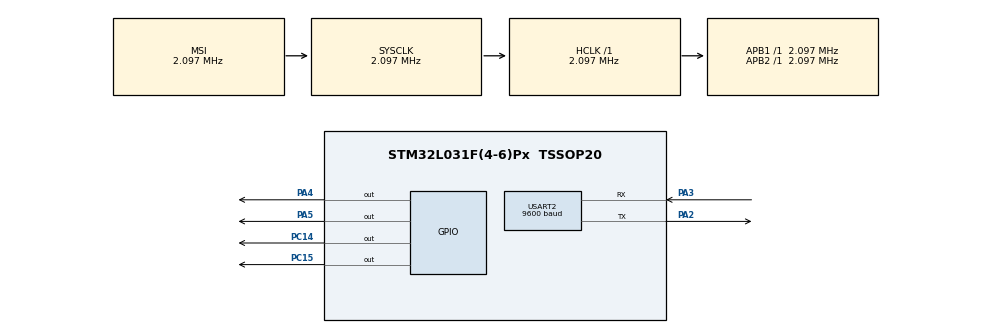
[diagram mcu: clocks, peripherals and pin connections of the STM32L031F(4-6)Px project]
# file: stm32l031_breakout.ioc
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Mcu.Family=STM32L0
Mcu.Name=STM32L031F(4-6)Px
Mcu.Package=TSSOP20
PA13.Mode=Serial_Wire
PA13.Signal=SYS_SWDIO
PA14.Mode=Serial_Wire
PA14.Signal=SYS_SWCLK
PA2.Mode=Asynchronous
PA2.Signal=USART2_TX
PA3.Mode=Asynchronous
PA3.Signal=USART2_RX
PA4.Signal=GPIO_Output
PA5.Signal=GPIO_Output
PC14-OSC32_IN.Signal=GPIO_Output
PC15-OSC32_OUT.Signal=GPIO_Output
ProjectManager.HeapSize=0x200
ProjectManager.StackSize=0x400
ProjectManager.TargetToolchain=SW4STM32
RCC.AHBFreq_Value=2097000
RCC.APB1Freq_Value=2097000
RCC.APB1TimFreq_Value=2097000
RCC.APB2Freq_Value=2097000
RCC.APB2TimFreq_Value=2097000
RCC.HSE_VALUE=8000000
RCC.HSI16_VALUE=16000000
RCC.HSI_VALUE=16000000
RCC.LSE_VALUE=32768
RCC.MSI_VALUE=2097000
RCC.SYSCLKFreq_VALUE=2097000
RCC.VCOOutputFreq_Value=48000000
USART2.BaudRate=9600
USART2.VirtualMode-Asynchronous=VM_ASYNC
board=custom

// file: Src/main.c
/* USER CODE BEGIN Header */
/**
  ******************************************************************************
  * @file           : main.c
  * @brief          : Main program body
  ******************************************************************************
  * @attention
  *
  * <h2><center>&copy; Copyright (c) 2019 STMicroelectronics.
  * All rights reserved.</center></h2>
  *
  * This software component is licensed by ST under BSD 3-Clause license,
  * the "License"; You may not use this file except in compliance with the
  * License. You may obtain a copy of the License at:
  *                        opensource.org/licenses/BSD-3-Clause
  *
  ******************************************************************************
  */
/* USER CODE END Header */

#include "main.h"
#include "usart.h"
#include "gpio.h"

void SystemClock_Config(void);

int main(void)
{

  /* MCU Configuration--------------------------------------------------------*/

  /* Reset of all peripherals, Initializes the Flash interface and the Systick. */
  HAL_Init();

  /* Configure the system clock */
  SystemClock_Config();

  /* Initialize all configured peripherals */
  MX_GPIO_Init();
  MX_USART2_UART_Init();
  /* USER CODE BEGIN 2 */

  HAL_GPIO_WritePin(GPIOA, GPIO_PIN_5, GPIO_PIN_SET);
  HAL_GPIO_WritePin(GPIOA, GPIO_PIN_4, GPIO_PIN_SET);
  HAL_GPIO_WritePin(GPIOC, GPIO_PIN_14|GPIO_PIN_15, GPIO_PIN_SET);
  /* USER CODE END 2 */

  /* Infinite loop */
  while (1)
  {

    /* USER CODE BEGIN 3 */
	HAL_GPIO_TogglePin(GPIOA, GPIO_PIN_5);
	HAL_Delay(500);

  }
  /* USER CODE END 3 */
}

void SystemClock_Config(void)
{
  RCC_OscInitTypeDef RCC_OscInitStruct = {0};
  RCC_ClkInitTypeDef RCC_ClkInitStruct = {0};
  RCC_PeriphCLKInitTypeDef PeriphClkInit = {0};

  /** Configure the main internal regulator output voltage
  */
  __HAL_PWR_VOLTAGESCALING_CONFIG(PWR_REGULATOR_VOLTAGE_SCALE1);
  /** Initializes the CPU, AHB and APB busses clocks
  */
  RCC_OscInitStruct.OscillatorType = RCC_OSCILLATORTYPE_MSI;
  RCC_OscInitStruct.MSIState = RCC_MSI_ON;
  RCC_OscInitStruct.MSICalibrationValue = 0;
  RCC_OscInitStruct.MSIClockRange = RCC_MSIRANGE_5;
  RCC_OscInitStruct.PLL.PLLState = RCC_PLL_NONE;
  if (HAL_RCC_OscConfig(&RCC_OscInitStruct) != HAL_OK)
  {
    Error_Handler();
  }
  /** Initializes the CPU, AHB and APB busses clocks
  */
  RCC_ClkInitStruct.ClockType = RCC_CLOCKTYPE_HCLK|RCC_CLOCKTYPE_SYSCLK
                              |RCC_CLOCKTYPE_PCLK1|RCC_CLOCKTYPE_PCLK2;
  RCC_ClkInitStruct.SYSCLKSource = RCC_SYSCLKSOURCE_MSI;
  RCC_ClkInitStruct.AHBCLKDivider = RCC_SYSCLK_DIV1;
  RCC_ClkInitStruct.APB1CLKDivider = RCC_HCLK_DIV1;
  RCC_ClkInitStruct.APB2CLKDivider = RCC_HCLK_DIV1;

  if (HAL_RCC_ClockConfig(&RCC_ClkInitStruct, FLASH_LATENCY_0) != HAL_OK)
  {
    Error_Handler();
  }
  PeriphClkInit.PeriphClockSelection = RCC_PERIPHCLK_USART2;
  PeriphClkInit.Usart2ClockSelection = RCC_USART2CLKSOURCE_PCLK1;
  if (HAL_RCCEx_PeriphCLKConfig(&PeriphClkInit) != HAL_OK)
  {
    Error_Handler();
  }
}

void Error_Handler(void)
{
}

/************************ (C) COPYRIGHT STMicroelectronics *****END OF FILE****/
